# G32F002 register map
File version: 1.0
CPU: CM0PLUS r0p1, little endian, no MPU, no FPU, 4 interrupt priority bits
Registers are 32-bit, read-write, reset 0x0 unless marked. A register's access mark holds for its fields unless they carry their own. Offsets are from the block's base; [hi:lo] are bit positions; lines under a group give offsets from that group; {n}, {i} and the like mark numbered series.

## ADC — Analog-to-digital converter
Base 0x4000B000
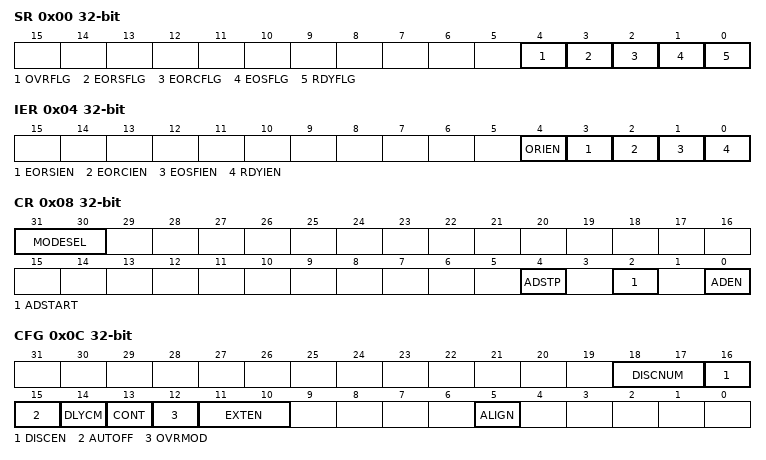
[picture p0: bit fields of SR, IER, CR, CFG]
0x00 SR — ADC interrupt and status register
  [4] OVRFLG — ADC group regular overrun flag
  [3] EORSFLG — ADC group regular end of sequence conversions flag
  [2] EORCFLG — ADC group regular end of unitary conversion flag
  [1] EOSFLG — ADC group regular end of sampling flag
  [0] RDYFLG — ADC Ready Flag
0x04 IER — ADC interrupt enable register
  [4] ORIEN — ADC group regular overrun interrupt
  [3] EORSIEN — ADC group regular end of sequence conversions interrupt
  [2] EORCIEN — ADC group regular end of unitary conversion interrupt
  [1] EOSFIEN — ADC group regular end of sampling interrupt
  [0] RDYIEN — ADC Ready Interrupt Enable
0x08 CR — ADC control register
  [31:30] MODESEL — ADC group mode select
  [4] ADSTP — ADC group regular conversion stop
  [2] ADSTART — ADC group regular conversion start
  [0] ADEN — ADC enable
0x0C CFG — ADC configuration register
  [18:17] DISCNUM — ADC group regular sequencer discontinuous number of ranks
  [16] DISCEN — ADC group regular sequencer discontinuous mode
  [15] AUTOFF — ADC low power auto wait
  [14] DLYCM — ADC delayed conversion mode
  [13] CONT — ADC group regular continuous conversion mode
  [12] OVRMOD — ADC group regular overrun configuration
  [11:10] EXTEN — ADC group regular external trigger polarity
  [5] ALIGN — Data alignment
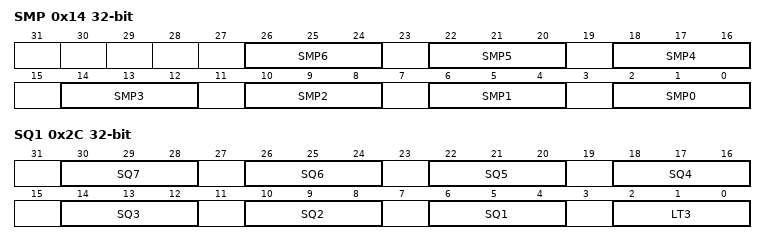
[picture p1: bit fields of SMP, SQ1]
0x14 SMP — ADC sampling time register 1
  [4n+2:4n] SMP{n} (n=0..6) — ADC channel {n} sampling time selection
0x2C SQ1 — ADC group regular sequencer register 1
  [4n+2:4n] SQ{n} (n=1..7) — ADC group regular sequencer rank {n}
  [2:0] LT3 — ADC group regular sequencer scan length
0x30 SQ2 — ADC group regular sequencer register 2
  [2:0] SQ8 — ADC group regular sequencer rank 8
0x38 DR ro — ADC group regular data register
  [15:0] RDATA — ADC group regular conversion data

## COMP0 — Comparator
Base 0x40005000
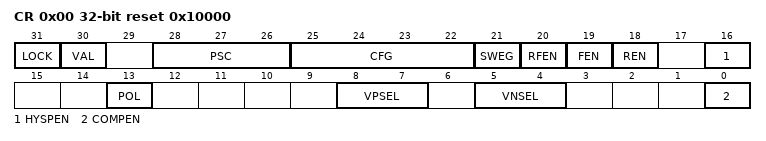
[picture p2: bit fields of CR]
0x00 CR access per field reset 0x10000 — Control Register
  [31] LOCK rw
  [30] VAL ro — Comparator outputs the level value before polarity selector and shielding.
  [28:26] PSC rw — Digital filter fractional division configuration
  [25:22] CFG rw — Digital filter fractional clock configuration
  [21] SWEG rw — soft interrupt
  [20] RFEN rw — Comparator interrupt rising and falling edge enable
  [19] FEN rw — Comparator interrupt falling edge enable
  [18] REN rw — Comparator interrupt rising edge enable
  [16] HYSPEN rw — Delay function enabled
  [13] POL rw — The output polarity of comparator .
  [8:7] VPSEL rw — Comparator positive input voltage select
  [5:4] VNSEL rw — Comparator negative input voltage select
  [0] COMPEN rw — Module enablement
0x04 ISR — Status register 0
  [0] IFLG — interrupt flag

## COMP1 — Comparator
Base 0x40006000
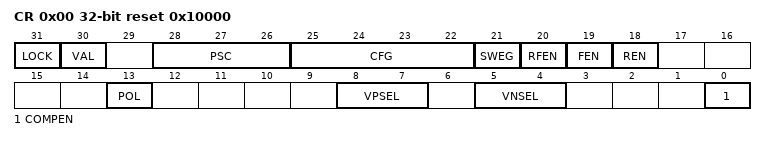
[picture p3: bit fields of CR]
0x00 CR access per field reset 0x10000 — Control Register 0
  [31] LOCK rw
  [30] VAL ro — Comparator outputs the level value before polarity selector and shielding.
  [28:26] PSC rw — Digital filter fractional division configuration
  [25:22] CFG rw — Digital filter fractional clock configuration
  [21] SWEG rw — soft interrupt
  [20] RFEN rw — Comparator interrupt rising and falling edge enable
  [19] FEN rw — Comparator interrupt falling edge enable
  [18] REN rw — Comparator interrupt rising edge enable
  [13] POL rw — The output polarity of comparator .
  [8:7] VPSEL rw — Comparator positive input voltage selection
  [5:4] VNSEL rw — Comparator negative input voltage selection
  [0] COMPEN rw — Module enablement
0x14 ISR — Status register
  [0] IFLG — interrupt flag

## FLASH — Flash memory controller
Base 0x40020400
0x00 WKEY — /
  [0] WKEY — Status 1: Unlocked. Status 0: Locked
0x04 MKEY — /
  [0] MKEY — Status 1: Unlocked. Status 0: Locked
0x0C NVRLKEY — /
  [0] NVRLKEY — Status 1: Unlocked. Status 0: Locked
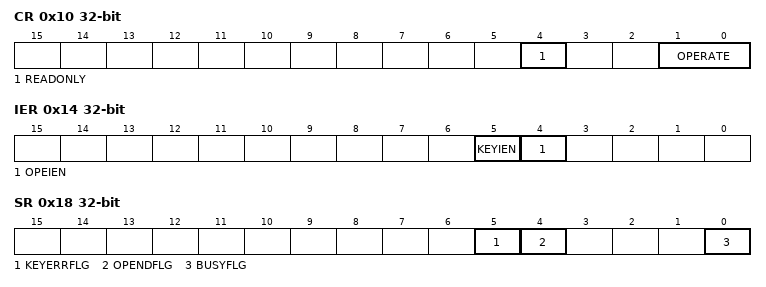
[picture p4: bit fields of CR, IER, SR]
0x10 CR — /
  [4] READONLY — Flash ip read-only control, cannot be erased/written.
  [1:0] OPERATE — Flash operation type configuration
0x14 IER — /
  [5] KEYIEN — Flash KEY Error Interrupt Enable
  [4] OPEIEN — FLSAH Erase End Interrupt Enable
0x18 SR access per field — /
  [5] KEYERRFLG rw — Flash KEY error interrupt, not unlocking flash erase.
  [4] OPENDFLG rw — FLASH erase finish interrupt
  [0] BUSYFLG ro — FLASH erase BUSY bit
0x1C CR1 reset 0x3 — /
  [1:0] LATENCY — The default value for the delay period on power-up at 64mhz (48mhz) is 2.

## CRC — Cryptographic processor
Base 0x40020800
0x00 DR — Data register
  [31:0] DATA — As an input register: stores new data for the CRC calculator when writing; As an output register: returns the result of the CRC calculation when reading.
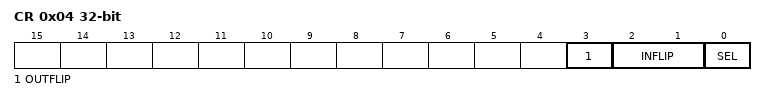
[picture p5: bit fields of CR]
0x04 CR — Control Register
  [3] OUTFLIP — Flip or not flip
  [2:1] INFLIP — Flip the input data in different units: do not flip, flip by byte, flip by half-word, flip by word.
  [0] SEL — 32-bit, 16-bit CRC selection
0x08 RSTDATA — Initial value data register
  [31:0] RSTDATA — Setting the initial value of CRC.

## GPIOA — General-purpose I/Os
Base 0x40020C00
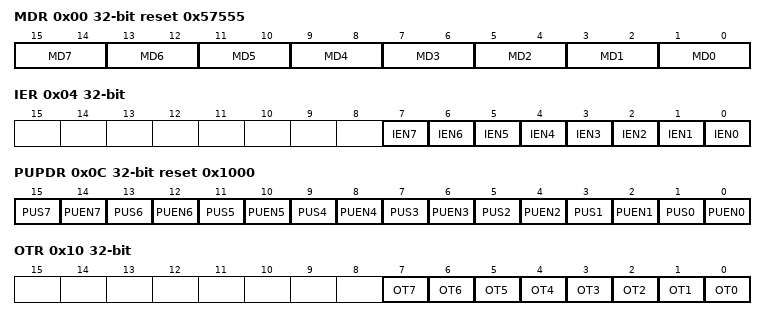
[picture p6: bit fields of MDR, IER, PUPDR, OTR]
0x00 MDR reset 0x57555
  [2n+1:2n] MD{n} (n=0..7) — /
0x04 IER
  [n] IEN{n} (n=0..7) — /
0x0C PUPDR reset 0x1000
  [2n+1] PUS{n} (n=0..7) — /
  [2n] PUEN{n} (n=0..7) — /
0x10 OTR
  [n] OT{n} (n=0..7) — /
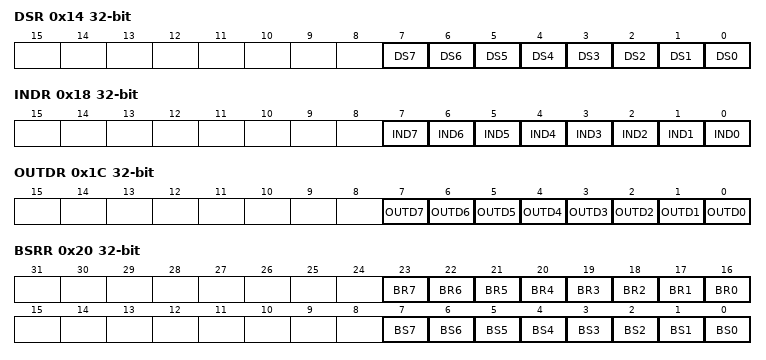
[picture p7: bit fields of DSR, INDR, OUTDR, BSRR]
0x14 DSR
  [n] DS{n} (n=0..7) — /
0x18 INDR
  [n] IND{n} (n=0..7) — /
0x1C OUTDR
  [n] OUTD{n} (n=0..7) — /
0x20 BSRR
  [n+16] BR{n} (n=0..7) — /
  [n] BS{n} (n=0..7) — /
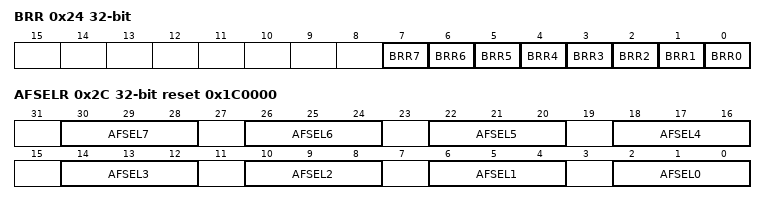
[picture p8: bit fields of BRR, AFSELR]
0x24 BRR
  [n] BRR{n} (n=0..7) — /
0x28 LOCK
  [31:0] KEY — /
0x2C AFSELR reset 0x1C0000
  [4n+2:4n] AFSEL{n} (n=0..7) — /

## GPIOB — General-purpose I/Os
Base 0x40021000
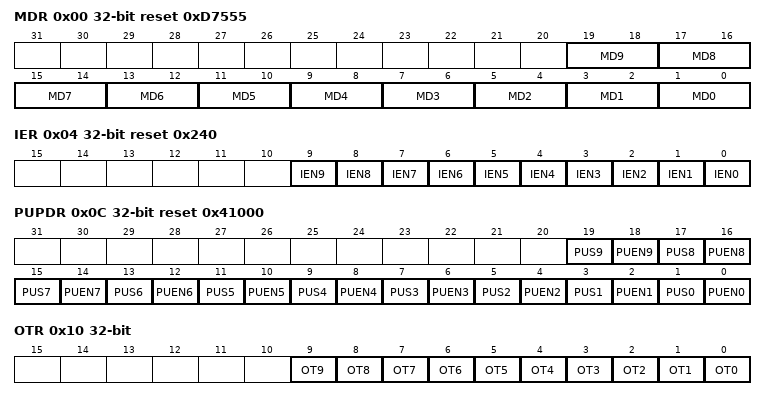
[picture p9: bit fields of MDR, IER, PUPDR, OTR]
0x00 MDR reset 0xD7555
  [2n+1:2n] MD{n} (n=0..9) — /
0x04 IER reset 0x240
  [n] IEN{n} (n=0..9) — /
0x0C PUPDR reset 0x41000
  [2n+1] PUS{n} (n=0..9) — /
  [2n] PUEN{n} (n=0..9) — /
0x10 OTR
  [n] OT{n} (n=0..9) — /
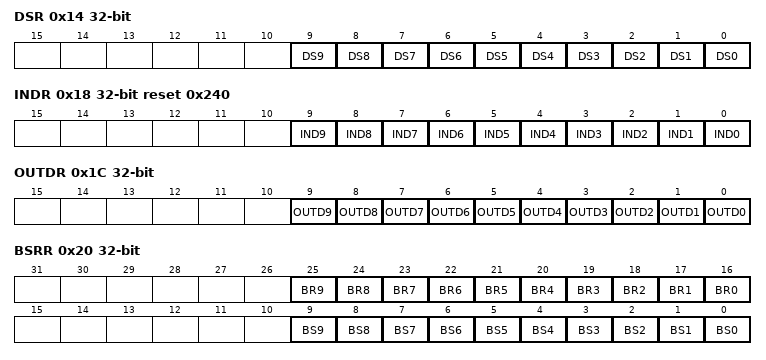
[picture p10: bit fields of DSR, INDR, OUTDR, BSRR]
0x14 DSR
  [n] DS{n} (n=0..9) — /
0x18 INDR reset 0x240
  [n] IND{n} (n=0..9) — /
0x1C OUTDR
  [n] OUTD{n} (n=0..9) — /
0x20 BSRR
  [n+16] BR{n} (n=0..9) — /
  [n] BS{n} (n=0..9) — /
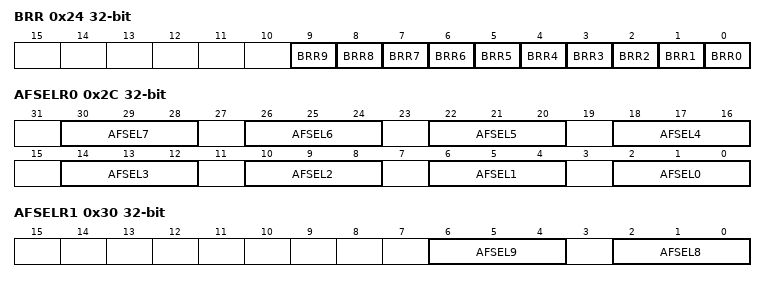
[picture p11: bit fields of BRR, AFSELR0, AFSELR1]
0x24 BRR
  [n] BRR{n} (n=0..9) — /
0x28 LOCK
  [31:0] KEY — /
0x2C AFSELR0
  [4n+2:4n] AFSEL{n} (n=0..7) — /
0x30 AFSELR1
  [6:4] AFSEL9 — /
  [2:0] AFSEL8 — /
